# CY8C4247AZS_M485 register map
File version: 0.1
PSoC 4200M
Registers are 32-bit, read-write, no defined reset value unless marked. A register's access mark holds for its fields unless they carry their own. Offsets are from the block's base; lines under a group give offsets from that group; [hi:lo] are bit positions; {n}, {i} and the like mark numbered series; 'fields as' and 'values as' point back to an identical list; <NAME> marks a mode.

## Memory map
0x00000000 Temp_Sensor_TMP05_STS
0x00000000 ADC — Sequencing SAR ADC
0x00000000 DMAC — DMAC Registers
0x00000000 Opamp
0x00000000 PWM_Blue
0x00000000 PWM_Green
0x00000000 PWM_Red
0x00000000 I2C — Serial Communication Block

## Temp_Sensor_TMP05_STS
Base 0x00000000
0x400F0063 Temp_Sensor_TMP05_STS_STATUS_REG 8-bit
0x400F0083 Temp_Sensor_TMP05_STS_MASK_REG 8-bit
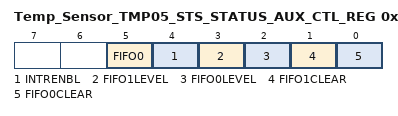
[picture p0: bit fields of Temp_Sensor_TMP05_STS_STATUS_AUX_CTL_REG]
0x400F0093 Temp_Sensor_TMP05_STS_STATUS_AUX_CTL_REG 8-bit
  [5] FIFO0 — FIFO0 clear
    1=ENABLED (Enable counter); 0=DISABLED (Disable counter)
  [4] INTRENBL — Enables or disables the Interrupt
    1=ENABLED (Interrupt enabled); 0=DISABLED (Interrupt disabled)
  [3] FIFO1LEVEL — FIFO level
    1=ENABLED (FIFO LVL: input mode: FIFO at least 1/2 empty; output mode: FIFO at least 1/2 full); 0=DISABLED (FIFO LVL: input mode: FIFO not full; output mode: FIFO not empty)
  [2] FIFO0LEVEL — FIFO level
    values as FIFO1LEVEL
  [1] FIFO1CLEAR — FIFO clear
    1=ENABLED (Clear FIFO state); 0=DISABLED (Normal FIFO operation)
  [0] FIFO0CLEAR — FIFO clear
    values as FIFO1CLEAR

## Opamp
Base 0x00000000
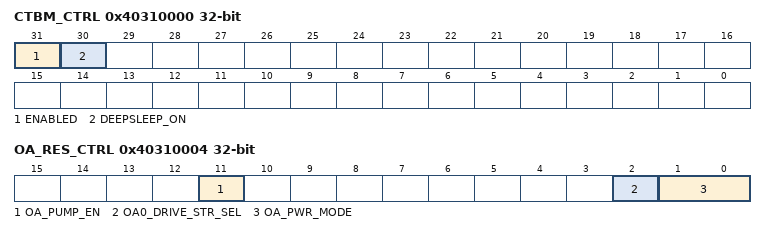
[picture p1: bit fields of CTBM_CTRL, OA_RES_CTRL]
0x40310000 CTBM_CTRL — Global CTB IP and power control
  [31] ENABLED — Selects component behavior in DeepSleep power mode
    0=DISABLE (CTB IP disabled (put analog in power down, open all switches)); 1=ENABLE (CTB IP enabledCTB IP enabled)
  [30] DEEPSLEEP_ON — Selects component behavior in DeepSleep power mode
    0=DISABLE (CTB IP disabled off during DeepSleep power mode); 1=ENABLE (CTB IP remains enabled during DeepSleep power mode (if ENABLED=1))
0x40310004 OA_RES_CTRL — Opamp and resistor control
  [11] OA_PUMP_EN — Selects pump
    0=DISABLE (Pump disabled); 1=ENABLE (Pump enabled)
  [2] OA0_DRIVE_STR_SEL — Opamp output strenght select
    0=Cy1x (Internal only); 1=Cy10x (Output to pin)
  [1:0] OA_PWR_MODE — Selects power for opamp
    0=OFF; 1=LOW (Low power); 2=MED (Medium power); 3=HIGH (High power)
0x40310F08 OA_COMP_TRIM — Opamp Compenation Capacitor Trim
  [1:0] OA_COMP_TRIM
    1=HIGH_SPEED; 2=BALANCED; 3=HIGH_STABILITY

## PWM_Blue
Base 0x00000000
0x40200288 COUNTER — Current counter value
0x4020028C CC — Compare / capture value
0x40200290 CC_BUF — Compare / capture buffer value
0x40200294 PERIOD — Period value
0x40200298 PERIOD_BUF — Period buffer value

## PWM_Green
Base 0x00000000
0x40200108 COUNTER — Current counter value
0x4020010C CC — Compare / capture value
0x40200110 CC_BUF — Compare / capture buffer value
0x40200114 PERIOD — Period value
0x40200118 PERIOD_BUF — Period buffer value

## PWM_Red
Base 0x00000000
0x40200148 COUNTER — Current counter value
0x4020014C CC — Compare / capture value
0x40200150 CC_BUF — Compare / capture buffer value
0x40200154 PERIOD — Period value
0x40200158 PERIOD_BUF — Period buffer value
